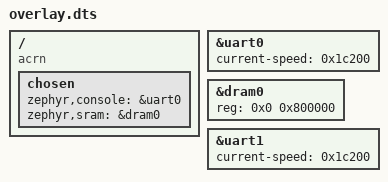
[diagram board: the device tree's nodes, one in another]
/ {
	compatible = "acrn";
	chosen {
		zephyr,console = &uart0;
		zephyr,sram = &dram0;
	};
};
&uart0{
	status = "okay";
	current-speed = < 0x1c200 >;
};
&dram0{
	reg = < 0x0 0x800000 >;
};
&uart1{
	status = "okay";
	current-speed = < 0x1c200 >;
};
